# CY8C5868AXI_LP035 register map
File version: 0.1
CY8C58LP
Registers are 8-bit, read-write, no defined reset value unless marked. A register's access mark holds for its fields unless they carry their own. Offsets are from the block's base; lines under a group give offsets from that group; [hi:lo] are bit positions; {n}, {i} and the like mark numbered series; 'fields as' and 'values as' point back to an identical list; <NAME> marks a mode.

## Memory map
0x40004394 USB size 0x1D0A — USBFS
0x400043AA ADC size 0x17E0

## USB — USBFS
Base 0x40004394
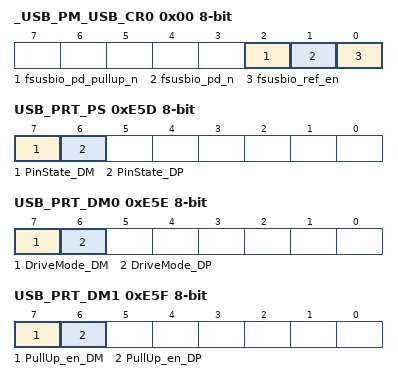
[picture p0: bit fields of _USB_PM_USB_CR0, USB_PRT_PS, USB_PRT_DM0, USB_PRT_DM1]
0x00 _USB_PM_USB_CR0 — USB Power Mode Control Register 0
  [2] fsusbio_pd_pullup_n, [1] fsusbio_pd_n, [0] fsusbio_ref_en
0x11 USB_PM_ACT_CFG — Active Power Mode Configuration Register
0x21 USB_PM_STBY_CFG — Standby Power Mode Configuration Register
0xE5D USB_PRT_PS — Port Pin State Register
  [7] PinState_DM ro, [6] PinState_DP ro
0xE5E USB_PRT_DM0 — Port Drive Mode Register
  [7] DriveMode_DM, [6] DriveMode_DP
0xE5F USB_PRT_DM1 — Port Drive Mode Register
  [7] PullUp_en_DM, [6] PullUp_en_DP
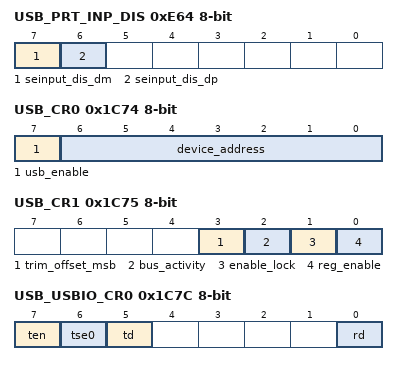
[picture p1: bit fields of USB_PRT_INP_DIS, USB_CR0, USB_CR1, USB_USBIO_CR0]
0xE64 USB_PRT_INP_DIS — Input buffer disable override
  [7] seinput_dis_dm, [6] seinput_dis_dp
0x1C6C USB_EP0_DR0 — bmRequestType
0x1C6D USB_EP0_DR1 — bRequest
0x1C6E USB_EP0_DR2 — wValueLo
0x1C6F USB_EP0_DR3 — wValueHi
0x1C70 USB_EP0_DR4 — wIndexLo
0x1C71 USB_EP0_DR5 — wIndexHi
0x1C72 USB_EP0_DR6 — lengthLo
0x1C73 USB_EP0_DR7 — lengthHi
0x1C74 USB_CR0 — USB Control Register 0
  [7] usb_enable, [6:0] device_address ro
0x1C75 USB_CR1 — USB Control Register 1
  [3] trim_offset_msb, [2] bus_activity, [1] enable_lock, [0] reg_enable
{0x1C6A+0x10*i} USB_SIE_EP{i}_CR0 (i=1..8) — The Endpoint{i} Control Register
0x1C7C USB_USBIO_CR0 — USBIO Control Register 0
  [7] ten, [6] tse0, [5] td, [0] rd ro
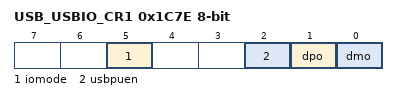
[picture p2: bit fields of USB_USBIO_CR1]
0x1C7E USB_USBIO_CR1 — USBIO Control Register 1
  [5] iomode, [2] usbpuen, [1] dpo ro, [0] dmo ro
0x1CF8 USB_BUF_SIZE — Dedicated Endpoint Buffer Size Register
0x1CFA USB_EP_ACTIVE — Endpoint Active Indication Register
0x1CFB USB_EP_TYPE — Endpoint Type (IN/OUT) Indication
0x1D09 USB_USB_CLK_EN — USB Block Clock Enable Register
